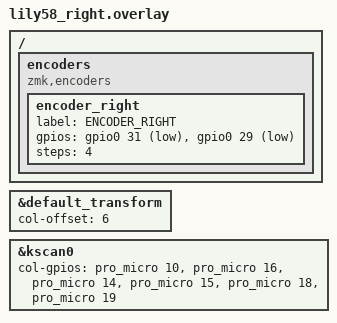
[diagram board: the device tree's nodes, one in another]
#include "lily58.dtsi"

&default_transform {
    col-offset = <6>;
};

&kscan0 {
    col-gpios
        = <&pro_micro 10 GPIO_ACTIVE_HIGH>
        , <&pro_micro 16 GPIO_ACTIVE_HIGH>
        , <&pro_micro 14 GPIO_ACTIVE_HIGH>
        , <&pro_micro 15 GPIO_ACTIVE_HIGH>
        , <&pro_micro 18 GPIO_ACTIVE_HIGH>
        , <&pro_micro 19 GPIO_ACTIVE_HIGH>
        ;
};

 / {
    encoders {
        compatible = "zmk,encoders";

        encoder_right: encoder_right {
            label = "ENCODER_RIGHT";
            gpios = <&gpio0 31 (GPIO_ACTIVE_LOW | GPIO_PULL_UP)>,
                    <&gpio0 29 (GPIO_ACTIVE_LOW | GPIO_PULL_UP)>;

            steps = <4>;
        };
    };
};
